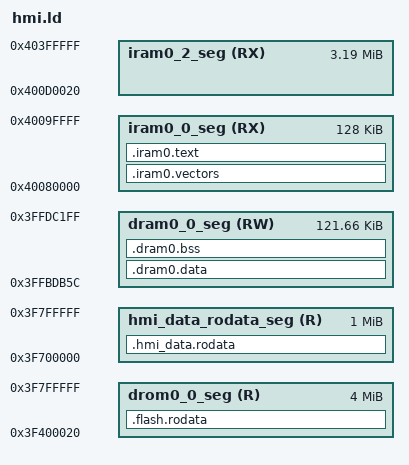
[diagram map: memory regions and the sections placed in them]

ENTRY( call_start_cpu0 );
MEMORY
{
  iram0_0_seg (RX) : org = 0x40080000, len = 0x20000
    iram0_2_seg (RX) : org = 0x400D0020, len = 0x330000-0x20
  
  dram0_0_seg (RW) : org = 0x3FFB0000 + 0xdb5c,
                                     len = 0x2c200 - 0xdb5c
  /* Flash mapped constant data */
  drom0_0_seg (R) : org = 0x3F400020, len = 0x400000-0x20

  hmi_data_rodata_seg (R):  org = 0x3F700000, len = 0x100000
}
_static_data_end = _bss_end;
/* Heap ends at top of dram0_0_seg */
_heap_end = 0x40000000 - 0x0;

  REGION_ALIAS("default_rodata_seg", drom0_0_seg);


PROVIDE ( START_HMI_DATA = 0x3F700000 );

SECTIONS
{

  /* Send .iram0 code to iram */
  .iram0.vectors :
  {
    _iram_start = ABSOLUTE(.);
    /* Vectors go to IRAM */
    _vector_table = ABSOLUTE(.);
    /* Vectors according to builds/RF-2015.2-win32/esp108_v1_2_s5_512int_2/config.html */
    . = 0x0;
    KEEP(*(.WindowVectors.text));
    . = 0x180;
    KEEP(*(.Level2InterruptVector.text));
    . = 0x1c0;
    KEEP(*(.Level3InterruptVector.text));
    . = 0x200;
    KEEP(*(.Level4InterruptVector.text));
    . = 0x240;
    KEEP(*(.Level5InterruptVector.text));
    . = 0x280;
    KEEP(*(.DebugExceptionVector.text));
    . = 0x2c0;
    KEEP(*(.NMIExceptionVector.text));
    . = 0x300;
    KEEP(*(.KernelExceptionVector.text));
    . = 0x340;
    KEEP(*(.UserExceptionVector.text));
    . = 0x3C0;
    KEEP(*(.DoubleExceptionVector.text));
    . = 0x400;
    _invalid_pc_placeholder = ABSOLUTE(.);
    *(.*Vector.literal)

    *(.UserEnter.literal);
    *(.UserEnter.text);
    . = ALIGN (16);
    *(.entry.text)
    *(.init.literal)
    *(.init)
    *(.fini.literal)
    *(.fini)

    _init_end = ABSOLUTE(.);
  } > iram0_0_seg
  
  .iram0.text :
  {
    /* Code marked as runnning out of IRAM */
    _iram_text_start = ABSOLUTE(.);

    *(.iram1 .iram1.*)
    *libgcc.a:lib2funcs.*(.literal .literal.* .text .text.*)
    *libgcov.a:(.literal .literal.* .text .text.*)
  } > iram0_0_seg

  .dram0.data :
  {
    _data_start = ABSOLUTE(.);
    *(.gnu.linkonce.d.*)
    *(.data1)
    *(.sdata)
    *(.sdata.*)
    *(.gnu.linkonce.s.*)
    *(.gnu.linkonce.s2.*)
    *(.jcr)
    _data_end = ABSOLUTE(.);
    . = ALIGN(4);
  } > dram0_0_seg

  /* Shared RAM */
  .dram0.bss (NOLOAD) :
  {
    . = ALIGN (8);
    _bss_start = ABSOLUTE(.);
    *(.dynbss .dynsbss .gnu.linkonce.b .gnu.linkonce.b.* .gnu.linkonce.sb .gnu.linkonce.sb.* .gnu.linkonce.sb2 .gnu.linkonce.sb2.* .sbss .sbss.* .sbss2 .sbss2.* .scommon .share.mem)
    . = ALIGN(4);
    . = ALIGN (8);
    _bss_end = ABSOLUTE(.);
  } > dram0_0_seg
  .flash.rodata : ALIGN(0x10)
  {
    _flash_rodata_start = ABSOLUTE(.);
    *(.irom1.text) /* catch stray ICACHE_RODATA_ATTR */
    *(.gnu.linkonce.r.*)
    *(.rodata1)
    __XT_EXCEPTION_TABLE_ = ABSOLUTE(.);
    *(.xt_except_table)
    *(.gcc_except_table .gcc_except_table.*)
    *(.gnu.linkonce.e.*)
    *(.gnu.version_r)
    . = (. + 3) & ~ 3;
    __eh_frame = ABSOLUTE(.);
    KEEP(*(.eh_frame))
    . = (. + 7) & ~ 3;
    /*  C++ constructor and destructor tables

        Make a point of not including anything from crtbegin.o or crtend.o, as IDF doesn't use toolchain crt
      */
    __init_array_start = ABSOLUTE(.);
    KEEP (*(EXCLUDE_FILE (*crtend.* *crtbegin.*) .ctors SORT(.ctors.*)))
    __init_array_end = ABSOLUTE(.);

    KEEP (*crtbegin.*(.dtors))
    KEEP (*(EXCLUDE_FILE (*crtend.*) .dtors))
    KEEP (*(SORT(.dtors.*)))
    KEEP (*(.dtors))
    /*  C++ exception handlers table:  */
    __XT_EXCEPTION_DESCS_ = ABSOLUTE(.);
    *(.xt_except_desc)
    *(.gnu.linkonce.h.*)
    __XT_EXCEPTION_DESCS_END__ = ABSOLUTE(.);
    *(.xt_except_desc_end)
    *(.dynamic)
    *(.gnu.version_d)
    /* Addresses of memory regions reserved via
       SOC_RESERVE_MEMORY_REGION() */
    _rodata_end = ABSOLUTE(.);
    /* Literals are also RO data. */
    _lit4_start = ABSOLUTE(.);
    *(*.lit4)
    *(.lit4.*)
    *(.gnu.linkonce.lit4.*)
    _lit4_end = ABSOLUTE(.);
    . = ALIGN(4);
    _thread_local_start = ABSOLUTE(.);
    *(.tdata)
    *(.tdata.*)
    *(.tbss)
    *(.tbss.*)
    _thread_local_end = ABSOLUTE(.);
    . = ALIGN(4);
  } >default_rodata_seg

    .hmi_data.rodata : ALIGN(0x10)
    {
        _hmi_data_rodata_start = ABSOLUTE(.);
        *(.extflashhdr)
        *(.extflash)
        *data_interface.*(.rodata .rodata.*)
        *bitmap_data.*(.rodata .rodata.*)
        *screen_data.*(.rodata .rodata.*)
        *event_data.*(.rodata .rodata.*)
        *menu_data.*(.rodata .rodata.*)
        *varstate_data.*(.rodata .rodata.*)
        _hmi_data_rodata_end = ABSOLUTE(.);
    } > hmi_data_rodata_seg
}
